# STM32F479 register map
File version: 2.0
CPU: CM4 r0p1, little endian, MPU, FPU, 4 interrupt priority bits
Registers are 32-bit, read-write, reset 0x0 unless marked. A register's access mark holds for its fields unless they carry their own. Offsets are from the block's base; [hi:lo] are bit positions.

## C_ADC — Common ADC registers
Base 0x40012300
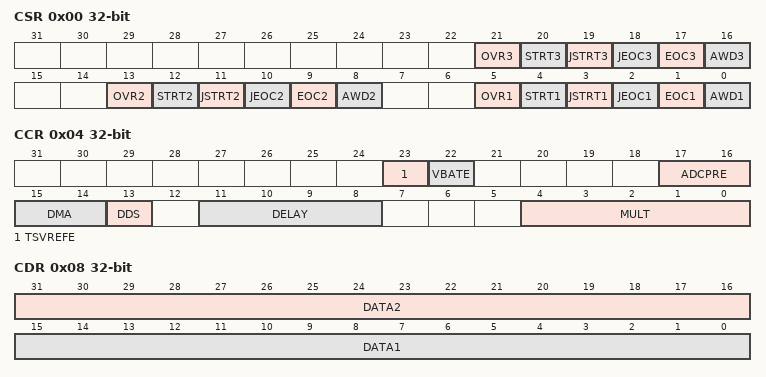
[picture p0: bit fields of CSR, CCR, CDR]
0x00 CSR ro — ADC Common status register
  [21] OVR3 — Overrun flag of ADC3
  [20] STRT3 — Regular channel Start flag of ADC 3
  [19] JSTRT3 — Injected channel Start flag of ADC 3
  [18] JEOC3 — Injected channel end of conversion of ADC 3
  [17] EOC3 — End of conversion of ADC 3
  [16] AWD3 — Analog watchdog flag of ADC 3
  [13] OVR2 — Overrun flag of ADC 2
  [12] STRT2 — Regular channel Start flag of ADC 2
  [11] JSTRT2 — Injected channel Start flag of ADC 2
  [10] JEOC2 — Injected channel end of conversion of ADC 2
  [9] EOC2 — End of conversion of ADC 2
  [8] AWD2 — Analog watchdog flag of ADC 2
  [5] OVR1 — Overrun flag of ADC 1
  [4] STRT1 — Regular channel Start flag of ADC 1
  [3] JSTRT1 — Injected channel Start flag of ADC 1
  [2] JEOC1 — Injected channel end of conversion of ADC 1
  [1] EOC1 — End of conversion of ADC 1
  [0] AWD1 — Analog watchdog flag of ADC 1
0x04 CCR — ADC common control register
  [23] TSVREFE — Temperature sensor and VREFINT enable
  [22] VBATE — VBAT enable
  [17:16] ADCPRE — ADC prescaler
  [15:14] DMA — Direct memory access mode for multi ADC mode
  [13] DDS — DMA disable selection for multi-ADC mode
  [11:8] DELAY — Delay between 2 sampling phases
  [4:0] MULT — Multi ADC mode selection
0x08 CDR ro — ADC common regular data register for dual and triple modes
  [31:16] DATA2 — 2nd data item of a pair of regular conversions
  [15:0] DATA1 — 1st data item of a pair of regular conversions

## DAC — Digital-to-analog converter
Base 0x40007400
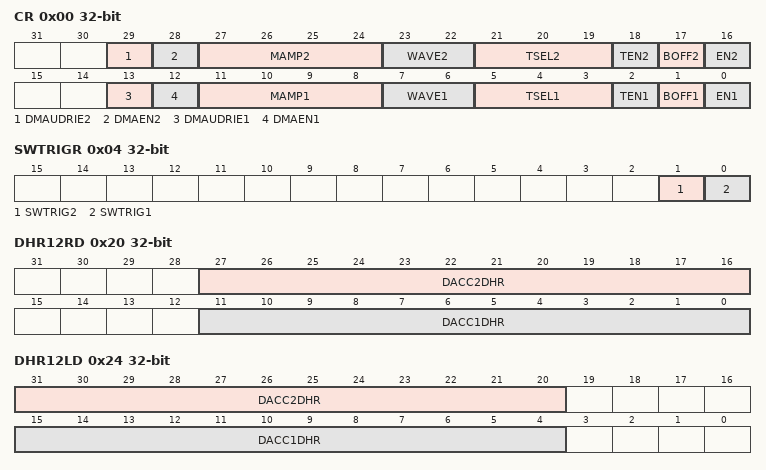
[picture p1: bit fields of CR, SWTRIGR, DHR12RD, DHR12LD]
0x00 CR — control register
  [29] DMAUDRIE2 — DAC channel2 DMA underrun interrupt enable
  [28] DMAEN2 — DAC channel2 DMA enable
  [27:24] MAMP2 — DAC channel2 mask/amplitude selector
  [23:22] WAVE2 — DAC channel2 noise/triangle wave generation enable
  [21:19] TSEL2 — DAC channel2 trigger selection
  [18] TEN2 — DAC channel2 trigger enable
  [17] BOFF2 — DAC channel2 output buffer disable
  [16] EN2 — DAC channel2 enable
  [13] DMAUDRIE1 — DAC channel1 DMA Underrun Interrupt enable
  [12] DMAEN1 — DAC channel1 DMA enable
  [11:8] MAMP1 — DAC channel1 mask/amplitude selector
  [7:6] WAVE1 — DAC channel1 noise/triangle wave generation enable
  [5:3] TSEL1 — DAC channel1 trigger selection
  [2] TEN1 — DAC channel1 trigger enable
  [1] BOFF1 — DAC channel1 output buffer disable
  [0] EN1 — DAC channel1 enable
0x04 SWTRIGR wo — software trigger register
  [1] SWTRIG2 — DAC channel2 software trigger
  [0] SWTRIG1 — DAC channel1 software trigger
0x08 DHR12R1 — channel1 12-bit right-aligned data holding register
  [11:0] DACC1DHR — DAC channel1 12-bit right-aligned data
0x0C DHR12L1 — channel1 12-bit left aligned data holding register
  [15:4] DACC1DHR — DAC channel1 12-bit left-aligned data
0x10 DHR8R1 — channel1 8-bit right aligned data holding register
  [7:0] DACC1DHR — DAC channel1 8-bit right-aligned data
0x14 DHR12R2 — channel2 12-bit right aligned data holding register
  [11:0] DACC2DHR — DAC channel2 12-bit right-aligned data
0x18 DHR12L2 — channel2 12-bit left aligned data holding register
  [15:4] DACC2DHR — DAC channel2 12-bit left-aligned data
0x1C DHR8R2 — channel2 8-bit right-aligned data holding register
  [7:0] DACC2DHR — DAC channel2 8-bit right-aligned data
0x20 DHR12RD — Dual DAC 12-bit right-aligned data holding register
  [27:16] DACC2DHR — DAC channel2 12-bit right-aligned data
  [11:0] DACC1DHR — DAC channel1 12-bit right-aligned data
0x24 DHR12LD — DUAL DAC 12-bit left aligned data holding register
  [31:20] DACC2DHR — DAC channel2 12-bit left-aligned data
  [15:4] DACC1DHR — DAC channel1 12-bit left-aligned data
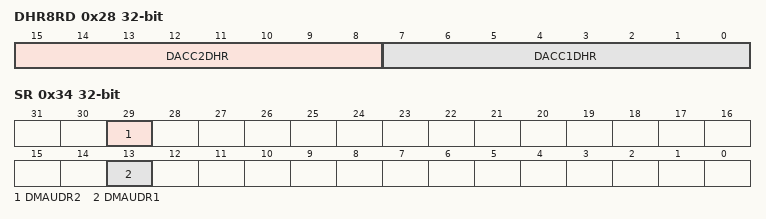
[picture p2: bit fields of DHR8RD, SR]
0x28 DHR8RD — DUAL DAC 8-bit right aligned data holding register
  [15:8] DACC2DHR — DAC channel2 8-bit right-aligned data
  [7:0] DACC1DHR — DAC channel1 8-bit right-aligned data
0x2C DOR1 ro — channel1 data output register
  [11:0] DACC1DOR — DAC channel1 data output
0x30 DOR2 ro — channel2 data output register
  [11:0] DACC2DOR — DAC channel2 data output
0x34 SR — status register
  [29] DMAUDR2 — DAC channel2 DMA underrun flag
  [13] DMAUDR1 — DAC channel1 DMA underrun flag
